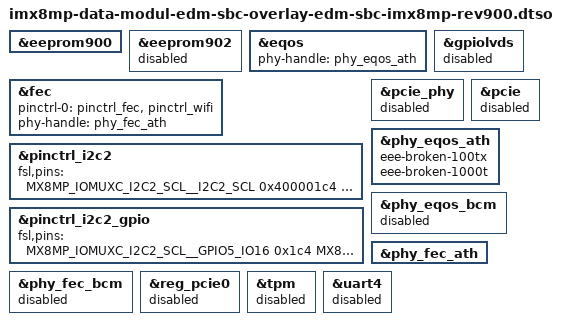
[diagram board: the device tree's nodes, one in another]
// SPDX-License-Identifier: (GPL-2.0+ OR MIT)
/*
 * Copyright (C) 2023-2026 Marek Vasut
 */
/dts-v1/;
/plugin/;

#include "imx8mp-pinfunc.h"

&eeprom900 {
	status = "okay";
};

&eeprom902 {
	status = "disabled";
};

&eqos {	/* First ethernet */
	phy-handle = <&phy_eqos_ath>;
};

&fec {	/* Second ethernet */
	/* pinctrl_wifi is ENET2_INT# */
	pinctrl-0 = <&pinctrl_fec &pinctrl_wifi>;
	phy-handle = <&phy_fec_ath>;
};

&gpiolvds {
	status = "disabled";
};

/*
 * External pull ups on R242 and R243 on I2C2_SCL_3V3 and I2C2_SDA_3V3
 * are not populated on this early board revision, activate in-SoC pull
 * up resistors instead to work around the missing external pull ups.
 */
&pinctrl_i2c2 {
	fsl,pins = <
		MX8MP_IOMUXC_I2C2_SCL__I2C2_SCL			0x400001c4
		MX8MP_IOMUXC_I2C2_SDA__I2C2_SDA			0x400001c4
	>;
};

&pinctrl_i2c2_gpio {
	fsl,pins = <
		MX8MP_IOMUXC_I2C2_SCL__GPIO5_IO16		0x1c4
		MX8MP_IOMUXC_I2C2_SDA__GPIO5_IO17		0x1c4
	>;
};

&pcie_phy {
	status = "disabled";
};

&pcie {
	status = "disabled";
};

&phy_eqos_ath {
	/*
	 * The software support for combination of EEE capable PHY and EEE
	 * capable MAC is so far missing from the Linux kernel. By default,
	 * the AR8035 PHY does enable EEE functionality on the PHY side,
	 * while the EQoS/DWMAC MAC expects to handle the EEE functionality
	 * on the MAC side. Because the Linux kernel is currently unable to
	 * align EEE configuration of the PHY and MAC, enabling EEE leads
	 * to unreliable link. Disable EEE until the kernel support is in
	 * place.
	 */
	eee-broken-100tx;
	eee-broken-1000t;
	status = "okay";
};

&phy_eqos_bcm {
	status = "disabled";
};

&phy_fec_ath {
	status = "okay";
};

&phy_fec_bcm {
	status = "disabled";
};

&reg_pcie0 {
	status = "disabled";
};

&tpm {
	status = "disabled";
};

&uart4 {
	status = "disabled";
};
